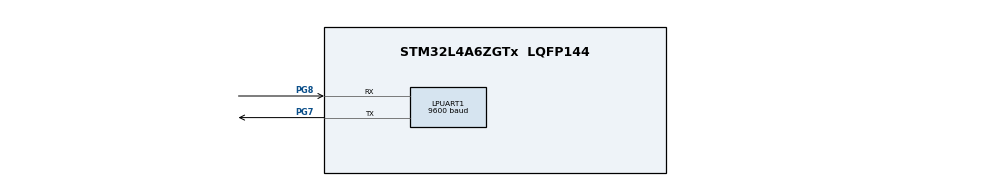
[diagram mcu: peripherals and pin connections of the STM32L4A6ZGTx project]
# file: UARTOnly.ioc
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FREERTOS.INCLUDE_xTaskAbortDelay=1
FREERTOS.Queues01=myQueue01,32,uint16_t,0,Dynamic,NULL,NULL
FREERTOS.Tasks01=defaultTask,0,128,thread1,Default,NULL,Dynamic,NULL,NULL
FREERTOS.Timers01=myTimer01,Callback01,osTimerPeriodic,Default,NULL,Dynamic,NULL
FREERTOS.configUSE_TIMERS=1
LPUART1.BaudRate=9600
LPUART1.WordLength=UART_WORDLENGTH_8B
Mcu.Family=STM32L4
Mcu.Name=STM32L4A6ZGTx
Mcu.Package=LQFP144
NVIC.FLASH_IRQn=true\:5\:0\:false\:false\:true\:true\:true\:true
NVIC.LPUART1_IRQn=true\:5\:0\:false\:true\:true\:3\:true\:true\:true
NVIC.PriorityGroup=NVIC_PRIORITYGROUP_4
NVIC.RCC_IRQn=true\:5\:0\:false\:true\:true\:1\:true\:true\:false
NVIC.TIM3_IRQn=true\:5\:0\:false\:true\:true\:2\:true\:true\:true
NVIC.TIM6_DAC_IRQn=true\:0\:0\:false\:false\:true\:false\:false\:true
NVIC.TimeBase=TIM6_DAC_IRQn
NVIC.TimeBaseIP=TIM6
PG7.Mode=Asynchronous
PG7.Signal=LPUART1_TX
PG8.Mode=Asynchronous
PG8.Signal=LPUART1_RX
PH0-OSC_IN\ (PH0).Mode=HSE-External-Clock-Source
PH0-OSC_IN\ (PH0).Signal=RCC_OSC_IN
ProjectManager.HeapSize=0x200
ProjectManager.StackSize=0x400
ProjectManager.TargetToolchain=EWARM V8.32
RCC.HSE_VALUE=8000000
RCC.HSI48_VALUE=48000000
RCC.HSI_VALUE=16000000
RCC.LSE_VALUE=32768
RCC.MSI_VALUE=4000000
RCC.VCOOutputFreq_Value=32000000
TIM3.Prescaler=16000
VP_FREERTOS_VS_CMSIS_V1.Mode=CMSIS_V1
VP_SYS_VS_tim6.Mode=TIM6
VP_TIM3_VS_ClockSourceINT.Mode=Internal
board=custom

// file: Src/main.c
/* USER CODE BEGIN Header */
/**
******************************************************************************
* @file           : main.c
* @brief          : Main program body
******************************************************************************
* @attention
*
* <h2><center>&copy; Copyright (c) 2019 STMicroelectronics.
* All rights reserved.</center></h2>
*
* This software component is licensed by ST under Ultimate Liberty license
* SLA0044, the "License"; You may not use this file except in compliance with
* the License. You may obtain a copy of the License at:
*                             www.st.com/SLA0044
*
******************************************************************************
*/
/* USER CODE END Header */

#include "main.h"
#include "cmsis_os.h"

UART_HandleTypeDef hlpuart1;
TIM_HandleTypeDef htim3;
osThreadId defaultTaskHandle;

osMessageQId myQueue01Handle;
osThreadId ReceiverHandle;

osTimerId myTimer01Handle;
/* USER CODE BEGIN PV */
__IO uint32_t uwPrescalerValue = 0;
TaskHandle_t xHandle = NULL;
QueueHandle_t xQueue = NULL;

typedef struct
{ uint8_t Value;} Data;
Data Rx_UART_Data;

uint8_t Timer_Buffer[32] = " Time Elapsed [sec]      \n";
int  size = 0 ,  Timer_Counter=0;
uint8_t Rx_Queue_Data;
/* USER CODE END PV */

void SystemClock_Config(void);
static void MX_GPIO_Init(void);
static void MX_LPUART1_UART_Init(void);
static void MX_TIM3_Init(void);
void Data_Processing(void const * argument);
void Callback01(void const * argument);

static void MX_NVIC_Init(void);

int main(void)
{

  /* MCU Configuration--------------------------------------------------------*/

  /* Reset of all peripherals, Initializes the Flash interface and the Systick. */
  HAL_Init();

  /* Configure the system clock */
  SystemClock_Config();

  /* Initialize all configured peripherals */
  MX_GPIO_Init();
  MX_LPUART1_UART_Init();
  MX_TIM3_Init();

  /* Initialize interrupts */
  MX_NVIC_Init();
  /* USER CODE BEGIN 2 */
  HAL_UART_Receive_IT(&hlpuart1, &Rx_UART_Data.Value ,1);
  /* USER CODE END 2 */

  /* Create the timer(s) */
  /* definition and creation of myTimer01 */
  osTimerDef(myTimer01, Callback01);
  myTimer01Handle = osTimerCreate(osTimer(myTimer01), osTimerPeriodic, NULL);

  /* Create the queue(s) */
  /* definition and creation of myQueue01 */
  //  osMessageQDef(myQueue01, 256, uint8_t);
  //  myQueue01Handle = osMessageCreate(osMessageQ(myQueue01), NULL);

  /* USER CODE BEGIN RTOS_QUEUES */
  /* add queues, ... */
  xQueue = xQueueCreate(256, sizeof(uint8_t));
  if (xQueue == NULL)
  {
    Error_Handler();
  }
  /* USER CODE END RTOS_QUEUES */

  /* Create the thread(s) */
  /* definition and creation of defaultTask */
  osThreadDef(defaultTask, Data_Processing, osPriorityNormal, 0, 128);
  defaultTaskHandle = osThreadCreate(osThread(defaultTask), NULL);

  /* Start scheduler */
  osKernelStart();

  /* We should never get here as control is now taken by the scheduler */

  /* Infinite loop */
  while (1)
  {

  }
}

void SystemClock_Config(void)
{
  RCC_OscInitTypeDef RCC_OscInitStruct = {0};
  RCC_ClkInitTypeDef RCC_ClkInitStruct = {0};
  RCC_PeriphCLKInitTypeDef PeriphClkInit = {0};

  /** Initializes the CPU, AHB and APB busses clocks
  */
  RCC_OscInitStruct.OscillatorType = RCC_OSCILLATORTYPE_MSI;
  RCC_OscInitStruct.MSIState = RCC_MSI_ON;
  RCC_OscInitStruct.MSICalibrationValue = 0;
  RCC_OscInitStruct.MSIClockRange = RCC_MSIRANGE_6;
  RCC_OscInitStruct.PLL.PLLState = RCC_PLL_NONE;
  if (HAL_RCC_OscConfig(&RCC_OscInitStruct) != HAL_OK)
  {
    Error_Handler();
  }
  /** Initializes the CPU, AHB and APB busses clocks
  */
  RCC_ClkInitStruct.ClockType = RCC_CLOCKTYPE_HCLK|RCC_CLOCKTYPE_SYSCLK
    |RCC_CLOCKTYPE_PCLK1|RCC_CLOCKTYPE_PCLK2;
  RCC_ClkInitStruct.SYSCLKSource = RCC_SYSCLKSOURCE_MSI;
  RCC_ClkInitStruct.AHBCLKDivider = RCC_SYSCLK_DIV1;
  RCC_ClkInitStruct.APB1CLKDivider = RCC_HCLK_DIV1;
  RCC_ClkInitStruct.APB2CLKDivider = RCC_HCLK_DIV1;

  if (HAL_RCC_ClockConfig(&RCC_ClkInitStruct, FLASH_LATENCY_0) != HAL_OK)
  {
    Error_Handler();
  }
  PeriphClkInit.PeriphClockSelection = RCC_PERIPHCLK_LPUART1;
  PeriphClkInit.Lpuart1ClockSelection = RCC_LPUART1CLKSOURCE_PCLK1;
  if (HAL_RCCEx_PeriphCLKConfig(&PeriphClkInit) != HAL_OK)
  {
    Error_Handler();
  }
  /** Configure the main internal regulator output voltage
  */
  if (HAL_PWREx_ControlVoltageScaling(PWR_REGULATOR_VOLTAGE_SCALE1) != HAL_OK)
  {
    Error_Handler();
  }
}

/**
* @brief NVIC Configuration.
* @retval None
*/
static void MX_NVIC_Init(void)
{
  /* RCC_IRQn interrupt configuration */
  HAL_NVIC_SetPriority(RCC_IRQn, 5, 0);
  HAL_NVIC_EnableIRQ(RCC_IRQn);
  /* TIM3_IRQn interrupt configuration */
  HAL_NVIC_SetPriority(TIM3_IRQn, 5, 0);
  HAL_NVIC_EnableIRQ(TIM3_IRQn);
  /* LPUART1_IRQn interrupt configuration */
  HAL_NVIC_SetPriority(LPUART1_IRQn, 5, 0);
  HAL_NVIC_EnableIRQ(LPUART1_IRQn);
}

static void MX_LPUART1_UART_Init(void)
{

  hlpuart1.Instance = LPUART1;
  hlpuart1.Init.BaudRate = 9600;
  hlpuart1.Init.WordLength = UART_WORDLENGTH_8B;
  hlpuart1.Init.StopBits = UART_STOPBITS_1;
  hlpuart1.Init.Parity = UART_PARITY_NONE;
  hlpuart1.Init.Mode = UART_MODE_TX_RX;
  hlpuart1.Init.HwFlowCtl = UART_HWCONTROL_NONE;
  hlpuart1.Init.OneBitSampling = UART_ONE_BIT_SAMPLE_DISABLE;
  hlpuart1.AdvancedInit.AdvFeatureInit = UART_ADVFEATURE_NO_INIT;
  if (HAL_UART_Init(&hlpuart1) != HAL_OK)
  {
    Error_Handler();
  }

}

static void MX_TIM3_Init(void)
{

  TIM_ClockConfigTypeDef sClockSourceConfig = {0};
  TIM_MasterConfigTypeDef sMasterConfig = {0};

  /* USER CODE BEGIN TIM3_Init 1 */
  uwPrescalerValue = (uint32_t)(SystemCoreClock / 10000) - 1;

  /* USER CODE END TIM3_Init 1 */
  htim3.Instance = TIM3;
  htim3.Init.Prescaler = uwPrescalerValue;
  htim3.Init.CounterMode = TIM_COUNTERMODE_UP;
  htim3.Init.Period = 9999;
  //htim3.Init.RepetitionCounter = 0;
  if (HAL_TIM_Base_Init(&htim3) != HAL_OK)
  {
    Error_Handler();
  }
  sClockSourceConfig.ClockSource = TIM_CLOCKSOURCE_INTERNAL;
  if (HAL_TIM_ConfigClockSource(&htim3, &sClockSourceConfig) != HAL_OK)
  {
    Error_Handler();
  }
  sMasterConfig.MasterOutputTrigger = TIM_TRGO_RESET;
  sMasterConfig.MasterSlaveMode = TIM_MASTERSLAVEMODE_DISABLE;
  if (HAL_TIMEx_MasterConfigSynchronization(&htim3, &sMasterConfig) != HAL_OK)
  {
    Error_Handler();
  }

}
static void MX_GPIO_Init(void)
{

  /* GPIO Ports Clock Enable */
  __HAL_RCC_GPIOH_CLK_ENABLE();
  __HAL_RCC_GPIOG_CLK_ENABLE();
  HAL_PWREx_EnableVddIO2();

}

/* USER CODE BEGIN 4 */

void HAL_UART_RxCpltCallback(UART_HandleTypeDef *huart)
{
  xQueueSendFromISR(xQueue, &Rx_UART_Data.Value, NULL);
  HAL_UART_Receive_IT(&hlpuart1, &Rx_UART_Data.Value, 1);
}

/* USER CODE END 4 */

void Data_Processing(void const * argument)
{
  /* USER CODE BEGIN 5 */
  int j;
  osTimerStart(myTimer01Handle,1000);
  /* Infinite loop */
  for(;;)
  {
    osDelay(500); // Task Periodicity
    size = 256 - uxQueueSpacesAvailable(xQueue); // get the size of received data
    if(size != 0)
    {
      for(j=0; j < size ; j++)  // loop to dequeue all received data
      {
        xQueueReceive(xQueue, &Rx_Queue_Data, 0);
        HAL_UART_Transmit_IT(&hlpuart1 , &Rx_Queue_Data , 1);
        while (hlpuart1.gState != 32)   // Wait for the end of the transfer to tansfer a new one
        {
        }
        if(Rx_Queue_Data =='S')
        {
          HAL_TIM_Base_Start_IT(&htim3);
        }
        else if(Rx_Queue_Data == 's')
        {
          HAL_TIM_Base_Stop_IT(&htim3);
          Timer_Counter=0;
        }

      }
    }
  }
  /* USER CODE END 5 */
}

/* Callback01 function */
void Callback01(void const * argument)
{
}

void HAL_TIM_PeriodElapsedCallback(TIM_HandleTypeDef *htim)
{
  if (htim->Instance == TIM6) {
    HAL_IncTick();
  }
  else
  {
    Timer_Counter++;
    snprintf((char *) Timer_Buffer+20, 30, "%d", Timer_Counter);
    HAL_UART_Transmit_IT(&hlpuart1, Timer_Buffer ,26);
  }
}

void Error_Handler(void)
{
}

/************************ (C) COPYRIGHT STMicroelectronics *****END OF FILE****/
